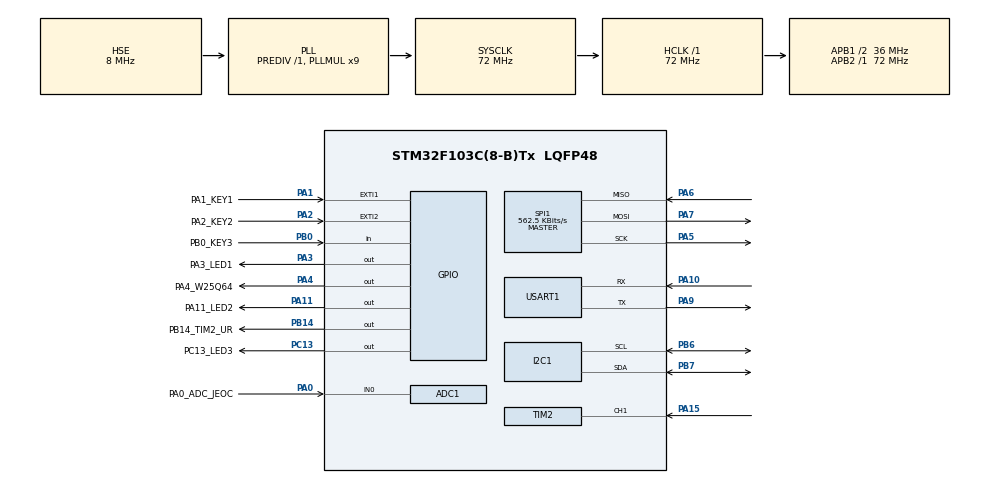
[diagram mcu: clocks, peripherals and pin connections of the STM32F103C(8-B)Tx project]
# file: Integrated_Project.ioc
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ADC1.Channel-1\#ChannelInjectedConversion=ADC_CHANNEL_0
ADC1.EnableInjectedConversion=ENABLE
ADC1.EnableRegularConversion=DISABLE
ADC1.ExternalTrigInjecConv=ADC_EXTERNALTRIGINJECCONV_T1_TRGO
ADC1.InjNumberOfConversion=1
ADC1.InjectedOffset-1\#ChannelInjectedConversion=0
ADC1.InjectedRank-1\#ChannelInjectedConversion=1
ADC1.SamplingTime-1\#ChannelInjectedConversion=ADC_SAMPLETIME_1CYCLE_5
ADC1.master=1
Dma.Request0=USART1_RX
Dma.Request1=USART1_TX
Dma.USART1_RX.0.Direction=DMA_PERIPH_TO_MEMORY
Dma.USART1_RX.0.Instance=DMA1_Channel5
Dma.USART1_RX.0.MemDataAlignment=DMA_MDATAALIGN_BYTE
Dma.USART1_RX.0.MemInc=DMA_MINC_ENABLE
Dma.USART1_RX.0.Mode=DMA_NORMAL
Dma.USART1_RX.0.PeriphDataAlignment=DMA_PDATAALIGN_BYTE
Dma.USART1_RX.0.PeriphInc=DMA_PINC_DISABLE
Dma.USART1_RX.0.Priority=DMA_PRIORITY_LOW
Dma.USART1_TX.1.Direction=DMA_MEMORY_TO_PERIPH
Dma.USART1_TX.1.Instance=DMA1_Channel4
Dma.USART1_TX.1.MemDataAlignment=DMA_MDATAALIGN_BYTE
Dma.USART1_TX.1.MemInc=DMA_MINC_ENABLE
Dma.USART1_TX.1.Mode=DMA_NORMAL
Dma.USART1_TX.1.PeriphDataAlignment=DMA_PDATAALIGN_BYTE
Dma.USART1_TX.1.PeriphInc=DMA_PINC_DISABLE
Dma.USART1_TX.1.Priority=DMA_PRIORITY_LOW
FREERTOS.BinarySemaphores01=KEY_BinarySem,Dynamic,NULL,Depleted;PS_BinarySem,Dynamic,NULL,Available;UR_BinarySem,Dynamic,NULL,Depleted
FREERTOS.CountingSemaphores01=USART_CountingSem,10,Dynamic,NULL,0
FREERTOS.Mutexes01=General_Mutex,Dynamic,NULL,Available
FREERTOS.Queues01=KEY_Queue,16,KEYMessage,0,Dynamic,NULL,NULL;USART_Queue,16,USARTMessage,0,Dynamic,NULL,NULL;OLED_Display_Queue,16,OLEDDisplayRequest,0,Dynamic,NULL,NULL;Sensor_Notify_Queue,8,SensorNotifyMsg,0,Dynamic,NULL,NULL
FREERTOS.Tasks01=KEY_Task,40,128,vIP_KEYTask,As weak,NULL,Dynamic,NULL,NULL;LED_Task,24,256,vIP_LEDTask,As weak,NULL,Dynamic,NULL,NULL;USART_Task,41,256,vIP_USARTTask,As weak,NULL,Dynamic,NULL,NULL;OLED_Task,25,128,vIP_OLEDTask,As weak,NULL,Dynamic,NULL,NULL;W25Q64_Task,26,256,vIP_W25Q64Task,As weak,NULL,Dynamic,NULL,NULL;PA11Flick_Task,8,64,vIP_PA11Flick,As weak,NULL,Dynamic,NULL,NULL;Test_CPU_usage,8,128,T_CPU_U_Task,As weak,NULL,Dynamic,NULL,NULL;PS_Task,8,128,vIP_PS_IJ_Task,As weak,NULL,Dynamic,NULL,NULL;UR_Task,8,128,vIP_UR_Task,As weak,NULL,Dynamic,NULL,NULL;CLI_Task,8,256,vIP_CLI_Task,As weak,NULL,Dynamic,NULL,NULL;PC13_Task,8,64,vIP_PC13_StartTask,As weak,NULL,Dynamic,NULL,NULL;ERR_Task,8,128,ERR_Printf_Task,As weak,NULL,Dynamic,NULL,NULL
FREERTOS.configMINIMAL_STACK_SIZE=64
FREERTOS.configTOTAL_HEAP_SIZE=10240
I2C1.I2C_Mode=I2C_Fast
Mcu.Family=STM32F1
Mcu.Name=STM32F103C(8-B)Tx
Mcu.Package=LQFP48
NVIC.ADC1_2_IRQn=true\:7\:0\:true\:false\:true\:true\:true\:true\:true
NVIC.DMA1_Channel4_IRQn=true\:5\:0\:false\:false\:true\:true\:false\:true\:true
NVIC.DMA1_Channel5_IRQn=true\:5\:0\:false\:false\:true\:true\:false\:true\:true
NVIC.EXTI1_IRQn=true\:10\:0\:true\:false\:true\:true\:true\:true\:true
NVIC.EXTI2_IRQn=true\:10\:0\:true\:false\:true\:true\:true\:true\:true
NVIC.PriorityGroup=NVIC_PRIORITYGROUP_4
NVIC.TIM2_IRQn=true\:6\:0\:true\:false\:true\:true\:true\:true\:true
NVIC.TIM3_IRQn=true\:9\:0\:true\:false\:true\:true\:true\:true\:true
NVIC.TIM4_IRQn=true\:15\:0\:false\:false\:true\:false\:false\:true\:true
NVIC.TimeBase=TIM4_IRQn
NVIC.TimeBaseIP=TIM4
NVIC.USART1_IRQn=true\:8\:0\:true\:false\:true\:true\:true\:true\:true
PA0-WKUP.GPIO_Label=PA0_ADC_JEOC
PA0-WKUP.Signal=ADCx_IN0
PA1.GPIO_Label=PA1_KEY1
PA1.GPIO_ModeDefaultEXTI=GPIO_MODE_IT_FALLING
PA1.GPIO_PuPd=GPIO_PULLUP
PA1.Signal=GPXTI1
PA10.Mode=Asynchronous
PA10.Signal=USART1_RX
PA11.GPIO_Label=PA11_LED2
PA11.Signal=GPIO_Output
PA13.Mode=Serial_Wire
PA13.Signal=SYS_JTMS-SWDIO
PA14.Mode=Serial_Wire
PA14.Signal=SYS_JTCK-SWCLK
PA15.Signal=S_TIM2_CH1_ETR
PA2.GPIO_Label=PA2_KEY2
PA2.GPIO_ModeDefaultEXTI=GPIO_MODE_IT_FALLING
PA2.GPIO_PuPd=GPIO_PULLUP
PA2.Signal=GPXTI2
PA3.GPIO_Label=PA3_LED1
PA3.GPIO_PuPd=GPIO_NOPULL
PA3.Signal=GPIO_Output
PA4.GPIO_Label=PA4_W25Q64
PA4.GPIO_PuPd=GPIO_NOPULL
PA4.GPIO_Speed=GPIO_SPEED_FREQ_LOW
PA4.PinState=GPIO_PIN_SET
PA4.Signal=GPIO_Output
PA5.Mode=Full_Duplex_Master
PA5.Signal=SPI1_SCK
PA6.Mode=Full_Duplex_Master
PA6.Signal=SPI1_MISO
PA7.Mode=Full_Duplex_Master
PA7.Signal=SPI1_MOSI
PA9.Mode=Asynchronous
PA9.Signal=USART1_TX
PB0.GPIO_Label=PB0_KEY3
PB0.GPIO_PuPd=GPIO_PULLUP
PB0.Signal=GPIO_Input
PB14.GPIO_Label=PB14_TIM2_UR
PB14.Signal=GPIO_Output
PB6.GPIO_Speed=GPIO_SPEED_FREQ_LOW
PB6.Mode=I2C
PB6.Signal=I2C1_SCL
PB7.GPIO_Speed=GPIO_SPEED_FREQ_LOW
PB7.Mode=I2C
PB7.Signal=I2C1_SDA
PC13-TAMPER-RTC.GPIO_Label=PC13_LED3
PC13-TAMPER-RTC.GPIO_ModeDefaultOutputPP=GPIO_MODE_OUTPUT_OD
PC13-TAMPER-RTC.GPIO_PuPd=GPIO_NOPULL
PC13-TAMPER-RTC.GPIO_Speed=GPIO_SPEED_FREQ_LOW
PC13-TAMPER-RTC.PinState=GPIO_PIN_SET
PC13-TAMPER-RTC.Signal=GPIO_Output
PD0-OSC_IN.Mode=HSE-External-Oscillator
PD0-OSC_IN.Signal=RCC_OSC_IN
PD1-OSC_OUT.Mode=HSE-External-Oscillator
PD1-OSC_OUT.Signal=RCC_OSC_OUT
ProjectManager.HeapSize=0x200
ProjectManager.StackSize=0x400
ProjectManager.TargetToolchain=MDK-ARM V5.32
RCC.ADCPresc=RCC_ADCPCLK2_DIV6
RCC.AHBFreq_Value=72000000
RCC.APB1CLKDivider=RCC_HCLK_DIV2
RCC.APB1Freq_Value=36000000
RCC.APB1TimFreq_Value=72000000
RCC.APB2Freq_Value=72000000
RCC.APB2TimFreq_Value=72000000
RCC.HCLKFreq_Value=72000000
RCC.PLLMUL=RCC_PLL_MUL9
RCC.PLLSourceVirtual=RCC_PLLSOURCE_HSE
RCC.SYSCLKFreq_VALUE=72000000
RCC.SYSCLKSource=RCC_SYSCLKSOURCE_PLLCLK
RCC.USBFreq_Value=72000000
SH.ADCx_IN0.0=ADC1_IN0,IN0
SH.S_TIM2_CH1_ETR.0=TIM2_CH1,Input_Capture1_from_TI1
SPI1.BaudRatePrescaler=SPI_BAUDRATEPRESCALER_128
SPI1.CalculateBaudRate=562.5 KBits/s
SPI1.Direction=SPI_DIRECTION_2LINES
SPI1.Mode=SPI_MODE_MASTER
SPI1.VirtualType=VM_MASTER
TIM1.Period=999
TIM1.Prescaler=71
TIM1.TIM_MasterOutputTrigger=TIM_TRGO_UPDATE
TIM2.AutoReloadPreload=TIM_AUTORELOAD_PRELOAD_ENABLE
TIM2.Channel-Input_Capture1_from_TI1=TIM_CHANNEL_1
TIM2.Channel-Input_Capture2_from_TI1_63=TIM_CHANNEL_2
TIM2.ICPolarity_CH2=TIM_INPUTCHANNELPOLARITY_FALLING
TIM2.Prescaler=71
TIM3.Period=5000 - 1
TIM3.Prescaler=71
USART1.VirtualMode=VM_ASYNC
VP_FREERTOS_VS_CMSIS_V2.Mode=CMSIS_V2
VP_SYS_VS_tim4.Mode=TIM4
VP_TIM1_VS_ClockSourceINT.Mode=Internal
VP_TIM2_VS_ClockSourceINT.Mode=Internal
VP_TIM2_VS_indirect_ch1.Mode=Input_Capture2_from_TI1_63
VP_TIM3_VS_ClockSourceINT.Mode=Internal
board=custom

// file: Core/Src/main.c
/* USER CODE BEGIN Header */
/**
  ******************************************************************************
  * @file           : main.c
  * @brief          : Main program body
  ******************************************************************************
  * @attention
  *
  * Copyright (c) 2026 STMicroelectronics.
  * All rights reserved.
  *
  * This software is licensed under terms that can be found in the LICENSE file
  * in the root directory of this software component.
  * If no LICENSE file comes with this software, it is provided AS-IS.
  *
  ******************************************************************************
  */
/* USER CODE END Header */
#include "main.h"
#include "cmsis_os.h"
#include "adc.h"
#include "dma.h"
#include "i2c.h"
#include "spi.h"
#include "tim.h"
#include "usart.h"
#include "gpio.h"

/* USER CODE BEGIN Includes */
#include "app_globals.h"   // g_state + 全部公共类型
#include "dwt.h"           // DWT_Init()
/* USER CODE END Includes */

void SystemClock_Config(void);
void MX_FREERTOS_Init(void);

int main(void)
{

  /* MCU Configuration--------------------------------------------------------*/

  /* Reset of all peripherals, Initializes the Flash interface and the Systick. */
  HAL_Init();

  /* USER CODE BEGIN Init */
  DWT_Init();
  /* USER CODE END Init */

  /* Configure the system clock */
  SystemClock_Config();

  /* Initialize all configured peripherals */
  MX_GPIO_Init();
  MX_DMA_Init();
  MX_USART1_UART_Init();
  MX_I2C1_Init();
  MX_SPI1_Init();
  MX_TIM3_Init();
  MX_ADC1_Init();
  MX_TIM1_Init();
  MX_TIM2_Init();
  /* USER CODE BEGIN 2 */
  //中断优先级重新分配
  HAL_NVIC_SetPriority(DMA1_Channel4_IRQn, 1, 0);  /* TX DMA: 最高 */
  HAL_NVIC_SetPriority(DMA1_Channel5_IRQn, 1, 0);  /* RX DMA: 最高 */
  HAL_NVIC_SetPriority(TIM2_IRQn,           6, 0);  /* 超声波捕获 */
  HAL_NVIC_SetPriority(ADC1_2_IRQn,         7, 0);  /* 光敏 JEOC   */
  HAL_NVIC_SetPriority(USART1_IRQn,         8, 0);  /* 串口       */
  HAL_NVIC_SetPriority(TIM3_IRQn,           9, 0);  /* CPU 测量   */
  HAL_NVIC_SetPriority(EXTI1_IRQn,         10, 0);  /* 按键1      */
  HAL_NVIC_SetPriority(EXTI2_IRQn,         10, 0);  /* 按键2      */
  /* USER CODE END 2 */

  /* Init scheduler */
  osKernelInitialize();  /* Call init function for freertos objects (in cmsis_os2.c) */
  MX_FREERTOS_Init();

  /* Start scheduler */
  osKernelStart();

  /* We should never get here as control is now taken by the scheduler */

  /* Infinite loop */
  while (1)
  {

  }
}

void SystemClock_Config(void)
{
  RCC_OscInitTypeDef RCC_OscInitStruct = {0};
  RCC_ClkInitTypeDef RCC_ClkInitStruct = {0};
  RCC_PeriphCLKInitTypeDef PeriphClkInit = {0};

  /** Initializes the RCC Oscillators according to the specified parameters
  * in the RCC_OscInitTypeDef structure.
  */
  RCC_OscInitStruct.OscillatorType = RCC_OSCILLATORTYPE_HSE;
  RCC_OscInitStruct.HSEState = RCC_HSE_ON;
  RCC_OscInitStruct.HSEPredivValue = RCC_HSE_PREDIV_DIV1;
  RCC_OscInitStruct.HSIState = RCC_HSI_ON;
  RCC_OscInitStruct.PLL.PLLState = RCC_PLL_ON;
  RCC_OscInitStruct.PLL.PLLSource = RCC_PLLSOURCE_HSE;
  RCC_OscInitStruct.PLL.PLLMUL = RCC_PLL_MUL9;
  if (HAL_RCC_OscConfig(&RCC_OscInitStruct) != HAL_OK)
  {
    Error_Handler();
  }

  /** Initializes the CPU, AHB and APB buses clocks
  */
  RCC_ClkInitStruct.ClockType = RCC_CLOCKTYPE_HCLK|RCC_CLOCKTYPE_SYSCLK
                              |RCC_CLOCKTYPE_PCLK1|RCC_CLOCKTYPE_PCLK2;
  RCC_ClkInitStruct.SYSCLKSource = RCC_SYSCLKSOURCE_PLLCLK;
  RCC_ClkInitStruct.AHBCLKDivider = RCC_SYSCLK_DIV1;
  RCC_ClkInitStruct.APB1CLKDivider = RCC_HCLK_DIV2;
  RCC_ClkInitStruct.APB2CLKDivider = RCC_HCLK_DIV1;

  if (HAL_RCC_ClockConfig(&RCC_ClkInitStruct, FLASH_LATENCY_2) != HAL_OK)
  {
    Error_Handler();
  }
  PeriphClkInit.PeriphClockSelection = RCC_PERIPHCLK_ADC;
  PeriphClkInit.AdcClockSelection = RCC_ADCPCLK2_DIV6;
  if (HAL_RCCEx_PeriphCLKConfig(&PeriphClkInit) != HAL_OK)
  {
    Error_Handler();
  }
}

void HAL_TIM_PeriodElapsedCallback(TIM_HandleTypeDef *htim)
{
  if (htim->Instance == TIM4)
  {
    HAL_IncTick();
  }
  /* USER CODE BEGIN Callback 1 */
  My_TIM3_PeriodElapsedCallback(htim);
  /* USER CODE END Callback 1 */
}

void Error_Handler(void)
{
  __disable_irq();
  while (1)
  {
  }
}

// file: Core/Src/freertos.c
/* USER CODE BEGIN Header */
/**
  ******************************************************************************
  * File Name          : freertos.c
  * Description        : Code for freertos applications
  ******************************************************************************
  * @attention
  *
  * Copyright (c) 2026 STMicroelectronics.
  * All rights reserved.
  *
  * This software is licensed under terms that can be found in the LICENSE file
  * in the root directory of this software component.
  * If no LICENSE file comes with this software, it is provided AS-IS.
  *
  ******************************************************************************
  */
/* USER CODE END Header */

#include "FreeRTOS.h"
#include "task.h"
#include "main.h"
#include "cmsis_os.h"

/* USER CODE BEGIN Includes */
#include "app_globals.h"
/* USER CODE END Includes */

/* Definitions for KEY_Task */
osThreadId_t KEY_TaskHandle;
const osThreadAttr_t KEY_Task_attributes = {
  .name = "KEY_Task",
  .stack_size = 128 * 4,
  .priority = (osPriority_t) osPriorityHigh,
};
/* Definitions for LED_Task */
osThreadId_t LED_TaskHandle;
const osThreadAttr_t LED_Task_attributes = {
  .name = "LED_Task",
  .stack_size = 256 * 4,
  .priority = (osPriority_t) osPriorityNormal,
};
/* Definitions for USART_Task */
osThreadId_t USART_TaskHandle;
const osThreadAttr_t USART_Task_attributes = {
  .name = "USART_Task",
  .stack_size = 256 * 4,
  .priority = (osPriority_t) osPriorityHigh1,
};
/* Definitions for OLED_Task */
osThreadId_t OLED_TaskHandle;
const osThreadAttr_t OLED_Task_attributes = {
  .name = "OLED_Task",
  .stack_size = 128 * 4,
  .priority = (osPriority_t) osPriorityNormal1,
};
/* Definitions for W25Q64_Task */
osThreadId_t W25Q64_TaskHandle;
const osThreadAttr_t W25Q64_Task_attributes = {
  .name = "W25Q64_Task",
  .stack_size = 256 * 4,
  .priority = (osPriority_t) osPriorityNormal2,
};
/* Definitions for PA11Flick_Task */
osThreadId_t PA11Flick_TaskHandle;
const osThreadAttr_t PA11Flick_Task_attributes = {
  .name = "PA11Flick_Task",
  .stack_size = 64 * 4,
  .priority = (osPriority_t) osPriorityLow,
};
/* Definitions for Test_CPU_usage */
osThreadId_t Test_CPU_usageHandle;
const osThreadAttr_t Test_CPU_usage_attributes = {
  .name = "Test_CPU_usage",
  .stack_size = 128 * 4,
  .priority = (osPriority_t) osPriorityLow,
};
/* Definitions for PS_Task */
osThreadId_t PS_TaskHandle;
const osThreadAttr_t PS_Task_attributes = {
  .name = "PS_Task",
  .stack_size = 128 * 4,
  .priority = (osPriority_t) osPriorityLow,
};
/* Definitions for UR_Task */
osThreadId_t UR_TaskHandle;
const osThreadAttr_t UR_Task_attributes = {
  .name = "UR_Task",
  .stack_size = 128 * 4,
  .priority = (osPriority_t) osPriorityLow,
};
/* Definitions for CLI_Task */
osThreadId_t CLI_TaskHandle;
const osThreadAttr_t CLI_Task_attributes = {
  .name = "CLI_Task",
  .stack_size = 256 * 4,
  .priority = (osPriority_t) osPriorityLow,
};
/* Definitions for PC13_Task */
osThreadId_t PC13_TaskHandle;
const osThreadAttr_t PC13_Task_attributes = {
  .name = "PC13_Task",
  .stack_size = 64 * 4,
  .priority = (osPriority_t) osPriorityLow,
};
/* Definitions for ERR_Task */
osThreadId_t ERR_TaskHandle;
const osThreadAttr_t ERR_Task_attributes = {
  .name = "ERR_Task",
  .stack_size = 128 * 4,
  .priority = (osPriority_t) osPriorityLow,
};
/* Definitions for KEY_Queue */
osMessageQueueId_t KEY_QueueHandle;
const osMessageQueueAttr_t KEY_Queue_attributes = {
  .name = "KEY_Queue"
};
/* Definitions for USART_Queue */
osMessageQueueId_t USART_QueueHandle;
const osMessageQueueAttr_t USART_Queue_attributes = {
  .name = "USART_Queue"
};
/* Definitions for OLED_Display_Queue */
osMessageQueueId_t OLED_Display_QueueHandle;
const osMessageQueueAttr_t OLED_Display_Queue_attributes = {
  .name = "OLED_Display_Queue"
};
/* Definitions for Sensor_Notify_Queue */
osMessageQueueId_t Sensor_Notify_QueueHandle;
const osMessageQueueAttr_t Sensor_Notify_Queue_attributes = {
  .name = "Sensor_Notify_Queue"
};
/* Definitions for General_Mutex */
osMutexId_t General_MutexHandle;
const osMutexAttr_t General_Mutex_attributes = {
  .name = "General_Mutex"
};
/* Definitions for KEY_BinarySem */
osSemaphoreId_t KEY_BinarySemHandle;
const osSemaphoreAttr_t KEY_BinarySem_attributes = {
  .name = "KEY_BinarySem"
};
/* Definitions for PS_BinarySem */
osSemaphoreId_t PS_BinarySemHandle;
const osSemaphoreAttr_t PS_BinarySem_attributes = {
  .name = "PS_BinarySem"
};
/* Definitions for UR_BinarySem */
osSemaphoreId_t UR_BinarySemHandle;
const osSemaphoreAttr_t UR_BinarySem_attributes = {
  .name = "UR_BinarySem"
};
/* Definitions for USART_CountingSem */
osSemaphoreId_t USART_CountingSemHandle;
const osSemaphoreAttr_t USART_CountingSem_attributes = {
  .name = "USART_CountingSem"
};

void vIP_KEYTask(void *argument);
void vIP_LEDTask(void *argument);
void vIP_USARTTask(void *argument);
void vIP_OLEDTask(void *argument);
void vIP_W25Q64Task(void *argument);
void vIP_PA11Flick(void *argument);
void T_CPU_U_Task(void *argument);
void vIP_PS_IJ_Task(void *argument);
void vIP_UR_Task(void *argument);
void vIP_CLI_Task(void *argument);
void vIP_PC13_StartTask(void *argument);
void ERR_Printf_Task(void *argument);

void MX_FREERTOS_Init(void); /* (MISRA C 2004 rule 8.1) */

void MX_FREERTOS_Init(void) {
  /* Create the mutex(es) */
  /* creation of General_Mutex */
  General_MutexHandle = osMutexNew(&General_Mutex_attributes);

  /* Create the semaphores(s) */
  /* creation of KEY_BinarySem */
  KEY_BinarySemHandle = osSemaphoreNew(1, 0, &KEY_BinarySem_attributes);

  /* creation of PS_BinarySem */
  PS_BinarySemHandle = osSemaphoreNew(1, 1, &PS_BinarySem_attributes);

  /* creation of UR_BinarySem */
  UR_BinarySemHandle = osSemaphoreNew(1, 0, &UR_BinarySem_attributes);

  /* creation of USART_CountingSem */
  USART_CountingSemHandle = osSemaphoreNew(10, 0, &USART_CountingSem_attributes);

  /* Create the queue(s) */
  /* creation of KEY_Queue */
  KEY_QueueHandle = osMessageQueueNew (16, sizeof(KEYMessage), &KEY_Queue_attributes);

  /* creation of USART_Queue */
  USART_QueueHandle = osMessageQueueNew (16, sizeof(USARTMessage), &USART_Queue_attributes);

  /* creation of OLED_Display_Queue */
  OLED_Display_QueueHandle = osMessageQueueNew (16, sizeof(OLEDDisplayRequest), &OLED_Display_Queue_attributes);

  /* creation of Sensor_Notify_Queue */
  Sensor_Notify_QueueHandle = osMessageQueueNew (8, sizeof(SensorNotifyMsg), &Sensor_Notify_Queue_attributes);

  /* Create the thread(s) */
  /* creation of KEY_Task */
  KEY_TaskHandle = osThreadNew(vIP_KEYTask, NULL, &KEY_Task_attributes);

  /* creation of LED_Task */
  LED_TaskHandle = osThreadNew(vIP_LEDTask, NULL, &LED_Task_attributes);

  /* creation of USART_Task */
  USART_TaskHandle = osThreadNew(vIP_USARTTask, NULL, &USART_Task_attributes);

  /* creation of OLED_Task */
  OLED_TaskHandle = osThreadNew(vIP_OLEDTask, NULL, &OLED_Task_attributes);

  /* creation of W25Q64_Task */
  W25Q64_TaskHandle = osThreadNew(vIP_W25Q64Task, NULL, &W25Q64_Task_attributes);

  /* creation of PA11Flick_Task */
  PA11Flick_TaskHandle = osThreadNew(vIP_PA11Flick, NULL, &PA11Flick_Task_attributes);

  /* creation of Test_CPU_usage */
  Test_CPU_usageHandle = osThreadNew(T_CPU_U_Task, NULL, &Test_CPU_usage_attributes);

  /* creation of PS_Task */
  PS_TaskHandle = osThreadNew(vIP_PS_IJ_Task, NULL, &PS_Task_attributes);

  /* creation of UR_Task */
  UR_TaskHandle = osThreadNew(vIP_UR_Task, NULL, &UR_Task_attributes);

  /* creation of CLI_Task */
  CLI_TaskHandle = osThreadNew(vIP_CLI_Task, NULL, &CLI_Task_attributes);

  /* creation of PC13_Task */
  PC13_TaskHandle = osThreadNew(vIP_PC13_StartTask, NULL, &PC13_Task_attributes);

  /* creation of ERR_Task */
  ERR_TaskHandle = osThreadNew(ERR_Printf_Task, NULL, &ERR_Task_attributes);

}

__weak void vIP_KEYTask(void *argument)
{
  for(;;)
  {
    osDelay(1);
  }
}

__weak void vIP_LEDTask(void *argument)
{
  for(;;)
  {
    osDelay(1);
  }
}

__weak void vIP_USARTTask(void *argument)
{
  for(;;)
  {
    osDelay(1);
  }
}

__weak void vIP_OLEDTask(void *argument)
{
  for(;;)
  {
    osDelay(1);
  }
}

__weak void vIP_W25Q64Task(void *argument)
{
  for(;;)
  {
    osDelay(1);
  }
}

__weak void vIP_PA11Flick(void *argument)
{
  for(;;)
  {
    osDelay(1);
  }
}

__weak void T_CPU_U_Task(void *argument)
{
  for(;;)
  {
    osDelay(1);
  }
}

__weak void vIP_PS_IJ_Task(void *argument)
{
  for(;;)
  {
    osDelay(1);
  }
}

__weak void vIP_UR_Task(void *argument)
{
  for(;;)
  {
    osDelay(1);
  }
}

__weak void vIP_CLI_Task(void *argument)
{
  for(;;)
  {
    osDelay(1);
  }
}

__weak void vIP_PC13_StartTask(void *argument)
{
  for(;;)
  {
    osDelay(1);
  }
}

__weak void ERR_Printf_Task(void *argument)
{
  for(;;)
  {
    osDelay(1);
  }
}
